# test_small register map
Vendor: ARM Ltd.; Series: ARMCM3; File version: 1.2
ARM 32-bit Cortex-M3 Microcontroller based device, CPU clock up to 80MHz, etc.
CPU: CM3 r1p0, little endian, MPU, no FPU, 3 interrupt priority bits
Registers are 32-bit, read-write, reset 0x0 unless marked. A register's access mark holds for its fields unless they carry their own. Offsets are from the block's base; lines under a group give offsets from that group; [hi:lo] are bit positions; {n}, {i} and the like mark numbered series; 'fields as' and 'values as' point back to an identical list; <NAME> marks a mode.

## Memory map
0x40010000 TIMER0 size 0x100 — 32 Timer / Counter, counting up or down from different sources
0x40080000 FOO size 0x100 — Just a peripheral to test this tool

## Interrupts
0 TIMER0 — Timer 0 interrupt
15 FOOIRQ (FOO) — Foo interrupt

## TIMER0 — 32 Timer / Counter, counting up or down from different sources
Base 0x40010000
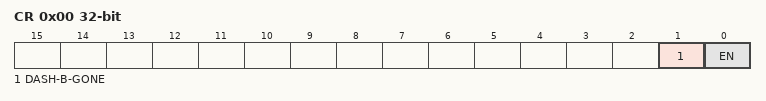
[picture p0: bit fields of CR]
0x00 CR — Control Register
  [1] DASH-B-GONE — Test that the name is adjusted
  [0] EN — Enable
    0=Disable (Timer is disabled and does not operate); 1=Enable (Timer is enabled and can operate)

## Licence text in the file
ARM Limited (ARM) is supplying this software for use with Cortex-M processor based microcontroller, but can be equally used for other suitable processor architectures. This file can be freely distributed. Modifications to this file shall be clearly marked. . THIS SOFTWARE IS PROVIDED "AS IS". NO WARRANTIES, WHETHER EXPRESS, IMPLIED. OR STATUTORY, INCLUDING, BUT NOT LIMITED TO, IMPLIED WARRANTIES OF. MERCHANTABILITY AND FITNESS FOR A PARTICULAR PURPOSE APPLY TO THIS SOFTWARE. ARM SHALL NOT, IN ANY CIRCUMSTANCES, BE LIABLE FOR SPECIAL, INCIDENTAL, OR. CONSEQUENTIAL DAMAGES, FOR ANY REASON WHATSOEVER.
